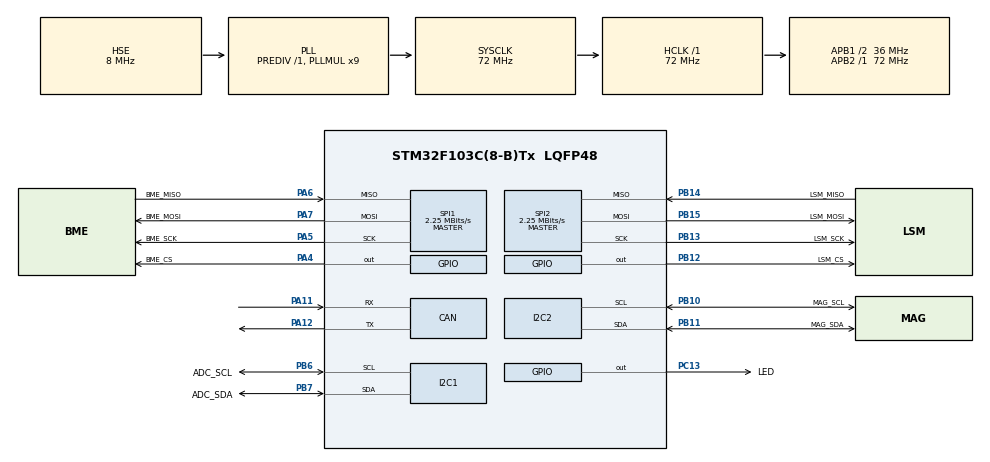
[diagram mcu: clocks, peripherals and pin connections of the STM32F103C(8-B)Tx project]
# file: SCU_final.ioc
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CAN.BS1=CAN_BS1_1TQ
CAN.BS2=CAN_BS2_1TQ
CAN.CalculateTimeBit=1333
CAN.CalculateTimeQuantum=444.44444444444446
Mcu.Family=STM32F1
Mcu.Name=STM32F103C(8-B)Tx
Mcu.Package=LQFP48
NVIC.PriorityGroup=NVIC_PRIORITYGROUP_4
PA11.Mode=Master
PA11.Signal=CAN_RX
PA12.Mode=Master
PA12.Signal=CAN_TX
PA13.Mode=Serial_Wire
PA13.Signal=SYS_JTMS-SWDIO
PA14.Mode=Serial_Wire
PA14.Signal=SYS_JTCK-SWCLK
PA4.GPIO_Label=BME_CS
PA4.GPIO_Speed=GPIO_SPEED_FREQ_HIGH
PA4.PinState=GPIO_PIN_SET
PA4.Signal=GPIO_Output
PA5.GPIO_Label=BME_SCK
PA5.Mode=Full_Duplex_Master
PA5.Signal=SPI1_SCK
PA6.GPIO_Label=BME_MISO
PA6.Mode=Full_Duplex_Master
PA6.Signal=SPI1_MISO
PA7.GPIO_Label=BME_MOSI
PA7.Mode=Full_Duplex_Master
PA7.Signal=SPI1_MOSI
PB10.GPIO_Label=MAG_SCL
PB10.Mode=I2C
PB10.Signal=I2C2_SCL
PB11.GPIO_Label=MAG_SDA
PB11.Mode=I2C
PB11.Signal=I2C2_SDA
PB12.GPIO_Label=LSM_CS
PB12.GPIO_Speed=GPIO_SPEED_FREQ_HIGH
PB12.PinState=GPIO_PIN_SET
PB12.Signal=GPIO_Output
PB13.GPIO_Label=LSM_SCK
PB13.Mode=Full_Duplex_Master
PB13.Signal=SPI2_SCK
PB14.GPIO_Label=LSM_MISO
PB14.Mode=Full_Duplex_Master
PB14.Signal=SPI2_MISO
PB15.GPIO_Label=LSM_MOSI
PB15.Mode=Full_Duplex_Master
PB15.Signal=SPI2_MOSI
PB6.GPIO_Label=ADC_SCL
PB6.Mode=I2C
PB6.Signal=I2C1_SCL
PB7.GPIO_Label=ADC_SDA
PB7.Mode=I2C
PB7.Signal=I2C1_SDA
PC13-TAMPER-RTC.GPIO_Label=LED
PC13-TAMPER-RTC.GPIO_ModeDefaultOutputPP=GPIO_MODE_OUTPUT_OD
PC13-TAMPER-RTC.GPIO_Speed=GPIO_SPEED_FREQ_HIGH
PC13-TAMPER-RTC.PinState=GPIO_PIN_SET
PC13-TAMPER-RTC.Signal=GPIO_Output
PD0-OSC_IN.Mode=HSE-External-Oscillator
PD0-OSC_IN.Signal=RCC_OSC_IN
PD1-OSC_OUT.Mode=HSE-External-Oscillator
PD1-OSC_OUT.Signal=RCC_OSC_OUT
ProjectManager.HeapSize=0x200
ProjectManager.StackSize=0x400
ProjectManager.TargetToolchain=SW4STM32
RCC.AHBFreq_Value=72000000
RCC.APB1CLKDivider=RCC_HCLK_DIV2
RCC.APB1Freq_Value=36000000
RCC.APB1TimFreq_Value=72000000
RCC.APB2Freq_Value=72000000
RCC.APB2TimFreq_Value=72000000
RCC.HCLKFreq_Value=72000000
RCC.LSE_VALUE=0.032768
RCC.PLLMUL=RCC_PLL_MUL9
RCC.PLLSourceVirtual=RCC_PLLSOURCE_HSE
RCC.SYSCLKFreq_VALUE=72000000
RCC.SYSCLKSource=RCC_SYSCLKSOURCE_PLLCLK
RCC.USBFreq_Value=72000000
SPI1.BaudRatePrescaler=SPI_BAUDRATEPRESCALER_32
SPI1.CalculateBaudRate=2.25 MBits/s
SPI1.Direction=SPI_DIRECTION_2LINES
SPI1.Mode=SPI_MODE_MASTER
SPI1.VirtualType=VM_MASTER
SPI2.BaudRatePrescaler=SPI_BAUDRATEPRESCALER_16
SPI2.CalculateBaudRate=2.25 MBits/s
SPI2.Direction=SPI_DIRECTION_2LINES
SPI2.Mode=SPI_MODE_MASTER
SPI2.VirtualType=VM_MASTER
board=custom

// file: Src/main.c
/* USER CODE BEGIN Header */
/**
  ******************************************************************************
  * @file           : main.c
  * @brief          : Main program body
  ******************************************************************************
  * @attention
  *
  * <h2><center>&copy; Copyright (c) 2019 STMicroelectronics.
  * All rights reserved.</center></h2>
  *
  * This software component is licensed by ST under BSD 3-Clause license,
  * the "License"; You may not use this file except in compliance with the
  * License. You may obtain a copy of the License at:
  *                        opensource.org/licenses/BSD-3-Clause
  *
  ******************************************************************************
  */
/* USER CODE END Header */

#include "main.h"

CAN_HandleTypeDef hcan;

I2C_HandleTypeDef hi2c1;
I2C_HandleTypeDef hi2c2;

SPI_HandleTypeDef hspi1;
SPI_HandleTypeDef hspi2;

void SystemClock_Config(void);
static void MX_GPIO_Init(void);
static void MX_CAN_Init(void);
static void MX_I2C1_Init(void);
static void MX_I2C2_Init(void);
static void MX_SPI1_Init(void);
static void MX_SPI2_Init(void);

/* USER CODE BEGIN 0 */
#include "the_main.h"
/* USER CODE END 0 */

int main(void)
{

  /* MCU Configuration--------------------------------------------------------*/

  /* Reset of all peripherals, Initializes the Flash interface and the Systick. */
  HAL_Init();

  /* Configure the system clock */
  SystemClock_Config();

  /* Initialize all configured peripherals */
  MX_GPIO_Init();
  MX_CAN_Init();
  MX_I2C1_Init();
  MX_I2C2_Init();
  MX_SPI1_Init();
  MX_SPI2_Init();
  /* USER CODE BEGIN 2 */

  the_main();
  /* USER CODE END 2 */

  /* Infinite loop */
  while (1)
  {
  }
}

void SystemClock_Config(void)
{
  RCC_OscInitTypeDef RCC_OscInitStruct = {0};
  RCC_ClkInitTypeDef RCC_ClkInitStruct = {0};

  /** Initializes the CPU, AHB and APB busses clocks
  */
  RCC_OscInitStruct.OscillatorType = RCC_OSCILLATORTYPE_HSE;
  RCC_OscInitStruct.HSEState = RCC_HSE_ON;
  RCC_OscInitStruct.HSEPredivValue = RCC_HSE_PREDIV_DIV1;
  RCC_OscInitStruct.HSIState = RCC_HSI_ON;
  RCC_OscInitStruct.PLL.PLLState = RCC_PLL_ON;
  RCC_OscInitStruct.PLL.PLLSource = RCC_PLLSOURCE_HSE;
  RCC_OscInitStruct.PLL.PLLMUL = RCC_PLL_MUL9;
  if (HAL_RCC_OscConfig(&RCC_OscInitStruct) != HAL_OK)
  {
    Error_Handler();
  }
  /** Initializes the CPU, AHB and APB busses clocks
  */
  RCC_ClkInitStruct.ClockType = RCC_CLOCKTYPE_HCLK|RCC_CLOCKTYPE_SYSCLK
                              |RCC_CLOCKTYPE_PCLK1|RCC_CLOCKTYPE_PCLK2;
  RCC_ClkInitStruct.SYSCLKSource = RCC_SYSCLKSOURCE_PLLCLK;
  RCC_ClkInitStruct.AHBCLKDivider = RCC_SYSCLK_DIV1;
  RCC_ClkInitStruct.APB1CLKDivider = RCC_HCLK_DIV2;
  RCC_ClkInitStruct.APB2CLKDivider = RCC_HCLK_DIV1;

  if (HAL_RCC_ClockConfig(&RCC_ClkInitStruct, FLASH_LATENCY_2) != HAL_OK)
  {
    Error_Handler();
  }
}

static void MX_CAN_Init(void)
{

  hcan.Instance = CAN1;
  hcan.Init.Prescaler = 16;
  hcan.Init.Mode = CAN_MODE_NORMAL;
  hcan.Init.SyncJumpWidth = CAN_SJW_1TQ;
  hcan.Init.TimeSeg1 = CAN_BS1_1TQ;
  hcan.Init.TimeSeg2 = CAN_BS2_1TQ;
  hcan.Init.TimeTriggeredMode = DISABLE;
  hcan.Init.AutoBusOff = DISABLE;
  hcan.Init.AutoWakeUp = DISABLE;
  hcan.Init.AutoRetransmission = DISABLE;
  hcan.Init.ReceiveFifoLocked = DISABLE;
  hcan.Init.TransmitFifoPriority = DISABLE;
  if (HAL_CAN_Init(&hcan) != HAL_OK)
  {
    Error_Handler();
  }

}

static void MX_I2C1_Init(void)
{

  hi2c1.Instance = I2C1;
  hi2c1.Init.ClockSpeed = 100000;
  hi2c1.Init.DutyCycle = I2C_DUTYCYCLE_2;
  hi2c1.Init.OwnAddress1 = 0;
  hi2c1.Init.AddressingMode = I2C_ADDRESSINGMODE_7BIT;
  hi2c1.Init.DualAddressMode = I2C_DUALADDRESS_DISABLE;
  hi2c1.Init.OwnAddress2 = 0;
  hi2c1.Init.GeneralCallMode = I2C_GENERALCALL_DISABLE;
  hi2c1.Init.NoStretchMode = I2C_NOSTRETCH_DISABLE;
  if (HAL_I2C_Init(&hi2c1) != HAL_OK)
  {
    Error_Handler();
  }

}

static void MX_I2C2_Init(void)
{

  hi2c2.Instance = I2C2;
  hi2c2.Init.ClockSpeed = 100000;
  hi2c2.Init.DutyCycle = I2C_DUTYCYCLE_2;
  hi2c2.Init.OwnAddress1 = 0;
  hi2c2.Init.AddressingMode = I2C_ADDRESSINGMODE_7BIT;
  hi2c2.Init.DualAddressMode = I2C_DUALADDRESS_DISABLE;
  hi2c2.Init.OwnAddress2 = 0;
  hi2c2.Init.GeneralCallMode = I2C_GENERALCALL_DISABLE;
  hi2c2.Init.NoStretchMode = I2C_NOSTRETCH_DISABLE;
  if (HAL_I2C_Init(&hi2c2) != HAL_OK)
  {
    Error_Handler();
  }

}

static void MX_SPI1_Init(void)
{

  /* SPI1 parameter configuration*/
  hspi1.Instance = SPI1;
  hspi1.Init.Mode = SPI_MODE_MASTER;
  hspi1.Init.Direction = SPI_DIRECTION_2LINES;
  hspi1.Init.DataSize = SPI_DATASIZE_8BIT;
  hspi1.Init.CLKPolarity = SPI_POLARITY_LOW;
  hspi1.Init.CLKPhase = SPI_PHASE_1EDGE;
  hspi1.Init.NSS = SPI_NSS_SOFT;
  hspi1.Init.BaudRatePrescaler = SPI_BAUDRATEPRESCALER_128;
  hspi1.Init.FirstBit = SPI_FIRSTBIT_MSB;
  hspi1.Init.TIMode = SPI_TIMODE_DISABLE;
  hspi1.Init.CRCCalculation = SPI_CRCCALCULATION_DISABLE;
  hspi1.Init.CRCPolynomial = 10;
  if (HAL_SPI_Init(&hspi1) != HAL_OK)
  {
    Error_Handler();
  }

}

static void MX_SPI2_Init(void)
{

  /* SPI2 parameter configuration*/
  hspi2.Instance = SPI2;
  hspi2.Init.Mode = SPI_MODE_MASTER;
  hspi2.Init.Direction = SPI_DIRECTION_2LINES;
  hspi2.Init.DataSize = SPI_DATASIZE_8BIT;
  hspi2.Init.CLKPolarity = SPI_POLARITY_LOW;
  hspi2.Init.CLKPhase = SPI_PHASE_1EDGE;
  hspi2.Init.NSS = SPI_NSS_SOFT;
  hspi2.Init.BaudRatePrescaler = SPI_BAUDRATEPRESCALER_16;
  hspi2.Init.FirstBit = SPI_FIRSTBIT_MSB;
  hspi2.Init.TIMode = SPI_TIMODE_DISABLE;
  hspi2.Init.CRCCalculation = SPI_CRCCALCULATION_DISABLE;
  hspi2.Init.CRCPolynomial = 10;
  if (HAL_SPI_Init(&hspi2) != HAL_OK)
  {
    Error_Handler();
  }

}

static void MX_GPIO_Init(void)
{
  GPIO_InitTypeDef GPIO_InitStruct = {0};

  /* GPIO Ports Clock Enable */
  __HAL_RCC_GPIOC_CLK_ENABLE();
  __HAL_RCC_GPIOD_CLK_ENABLE();
  __HAL_RCC_GPIOA_CLK_ENABLE();
  __HAL_RCC_GPIOB_CLK_ENABLE();

  /*Configure GPIO pin Output Level */
  HAL_GPIO_WritePin(LED_GPIO_Port, LED_Pin, GPIO_PIN_SET);

  /*Configure GPIO pin Output Level */
  HAL_GPIO_WritePin(BME_CS_GPIO_Port, BME_CS_Pin, GPIO_PIN_SET);

  /*Configure GPIO pin Output Level */
  HAL_GPIO_WritePin(LSM_CS_GPIO_Port, LSM_CS_Pin, GPIO_PIN_SET);

  /*Configure GPIO pin : LED_Pin */
  GPIO_InitStruct.Pin = LED_Pin;
  GPIO_InitStruct.Mode = GPIO_MODE_OUTPUT_OD;
  GPIO_InitStruct.Pull = GPIO_NOPULL;
  GPIO_InitStruct.Speed = GPIO_SPEED_FREQ_HIGH;
  HAL_GPIO_Init(LED_GPIO_Port, &GPIO_InitStruct);

  /*Configure GPIO pin : BME_CS_Pin */
  GPIO_InitStruct.Pin = BME_CS_Pin;
  GPIO_InitStruct.Mode = GPIO_MODE_OUTPUT_PP;
  GPIO_InitStruct.Pull = GPIO_NOPULL;
  GPIO_InitStruct.Speed = GPIO_SPEED_FREQ_HIGH;
  HAL_GPIO_Init(BME_CS_GPIO_Port, &GPIO_InitStruct);

  /*Configure GPIO pin : LSM_CS_Pin */
  GPIO_InitStruct.Pin = LSM_CS_Pin;
  GPIO_InitStruct.Mode = GPIO_MODE_OUTPUT_PP;
  GPIO_InitStruct.Pull = GPIO_NOPULL;
  GPIO_InitStruct.Speed = GPIO_SPEED_FREQ_HIGH;
  HAL_GPIO_Init(LSM_CS_GPIO_Port, &GPIO_InitStruct);

}

void Error_Handler(void)
{
  /* USER CODE BEGIN Error_Handler_Debug */
  /* User can add his own implementation to report the HAL error return state */
  NVIC_SystemReset();
  /* USER CODE END Error_Handler_Debug */
}

/************************ (C) COPYRIGHT STMicroelectronics *****END OF FILE****/
